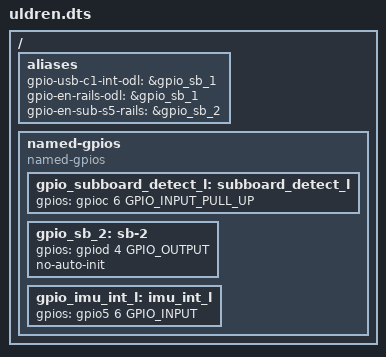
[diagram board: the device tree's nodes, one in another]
/* Copyright 2023 The ChromiumOS Authors
 * Use of this source code is governed by a BSD-style license that can be
 * found in the LICENSE file.
 */

#include "generic_npcx.dts"
#include <dt-bindings/pwm/pwm.h>
#include "../program/nissa/uldren/cbi.dtsi"

/ {
    aliases {
          gpio-usb-c1-int-odl = &gpio_sb_1;
          gpio-en-rails-odl = &gpio_sb_1;
          gpio-en-sub-s5-rails = &gpio_sb_2;
      };
    named-gpios {
		  compatible = "named-gpios";

      /delete-node/ hdmi_sel;

      gpio_subboard_detect_l: subboard_detect_l {
			  gpios = <&gpioc 6 GPIO_INPUT_PULL_UP>;
      };
      gpio_sb_2: sb-2 {
          gpios = <&gpiod 4 GPIO_OUTPUT>;
          no-auto-init;
      };
      gpio_imu_int_l: imu_int_l {
			    gpios = <&gpio5 6 GPIO_INPUT>;
		};
    };    
};
